AUTOSAR XML (schema 4.0)
package /If
  client server interface CsDiagIf
    operation GetStatus
      arg status
  sender receiver interface SrSpeedIf
    data Speed
package /SwComponentType
  application sw component type ServerSwc
    provide port PpDiag: provided-interface=CsDiagIf
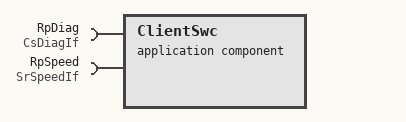
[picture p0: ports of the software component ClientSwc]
  application sw component type ClientSwc
    require port RpDiag: required-interface=CsDiagIf
    require port RpSpeed: required-interface=SrSpeedIf
  composition sw component type TopComp
    component srv: type=ServerSwc
    component cli: type=ClientSwc
    connect srv.PpDiag -> cli.RpDiag
